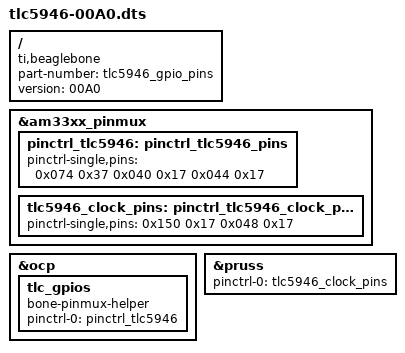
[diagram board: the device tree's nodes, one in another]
/dts-v1/;
/plugin/;

/ {
    	compatible = "ti,beaglebone", "ti,beaglebone-black";

	/* identification */
    	part-number = "tlc5946_gpio_pins";
	version = "00A0";

	/******************************************/
	/* pinmuxing                              */
	/*                                        */
    	fragment@0 {
        	target = <&am33xx_pinmux>;
        	__overlay__ {
            		pinctrl_tlc5946: pinctrl_tlc5946_pins {
                		pinctrl-single,pins = <
                 			0x074 0x37 /* xerr:  P9_13 = uart4_txd, INPUT_PULLUP  | MODE7 */
	                 		0x040 0x17 /* mode:  P9_15 = gpio1_16,  OUTPUT_PULLUP | MODE7 */
					//0x150 0x17 /* blank: P9_22 = UART2_RXD, OUTPUT_PULLUP | MODE7 */
                	 		0x044 0x17 /* xhalf: P9_23 = gpio1_17,  OUTPUT_PULLUP | MODE7 */
					//0x048 0x17 /* gsclk: P9_14 = EHRPWM1A,  OUTPUT_PULLUP | MODE7 */
             			>;
            		};
        	};
    	};
    	fragment@1 {
        	target = <&am33xx_pinmux>;
        	__overlay__ {
            		tlc5946_clock_pins: pinctrl_tlc5946_clock_pins {
                		pinctrl-single,pins = <
                 			//0x074 0x37 /* xerr:  P9_13 = uart4_txd, INPUT_PULLUP  | MODE7 */
	                 		//0x040 0x17 /* mode:  P9_15 = gpio1_16,  OUTPUT_PULLUP | MODE7 */
					0x150 0x17 /* blank: P9_22 = UART2_RXD, OUTPUT_PULLUP | MODE7 */
                	 		//0x044 0x17 /* xhalf: P9_23 = gpio1_17,  OUTPUT_PULLUP | MODE7 */
					0x048 0x17 /* gsclk: P9_14 = EHRPWM1A,  OUTPUT_PULLUP | MODE7 */
             			>;
            		};
        	};
    	};

	/******************************************/
	/* GPIO pins                              */
	/*                                        */
	fragment@20 {
		target = <&ocp>;
		__overlay__ {
			#address-cells = <1>;
			#size-cells = <1>;
			tlc_gpios {
				compatible = "bone-pinmux-helper";
				pinctrl-names = "default";
				pinctrl-0 = <&pinctrl_tlc5946>;
				status = "okay";
			};
		};
	};

	/******************************************/
	/* Enable PRUSS                           */
	/*                                        */
	fragment@30 {
		target = <&pruss>;
		__overlay__ {
			status = "okay";

			pinctrl-names = "default";
			pinctrl-0 = <&tlc5946_clock_pins>; 
		};
	};


};

